# A31G324 register map
Vendor: ABOV Semiconductor Co., Ltd.; Series: A31G324; File version: 1.0
CPU: CM0PLUS r0p1, little endian, no MPU, no FPU, VTOR, 2 interrupt priority bits
Registers are 32-bit, read-write, reset 0x0 unless marked. A register's access mark holds for its fields unless they carry their own. Offsets are from the block's base; [hi:lo] are bit positions; {n}, {i} and the like mark numbered series.

## PA — General Port A
Base 0x40001000
Same registers: PB 0x40001100, PC 0x40001200
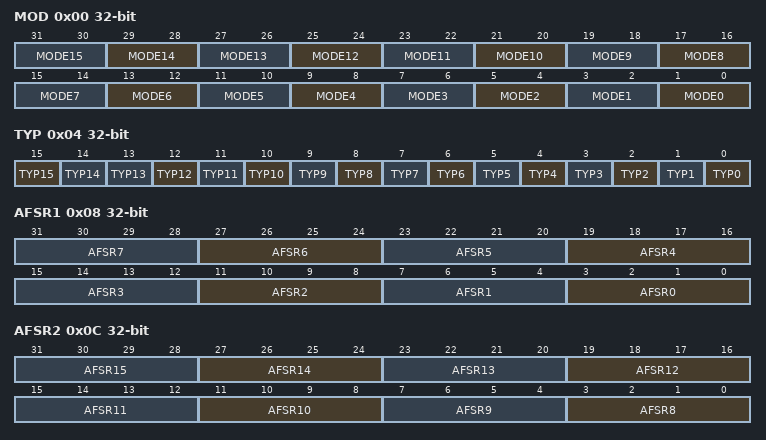
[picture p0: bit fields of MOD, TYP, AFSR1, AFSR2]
0x00 MOD — Port n Mode Register
  [2n+1:2n] MODE{n} (n=0..15) — Pin {n} Mode Selection bits
0x04 TYP — Port n Output Type Selection Register
  [15] TYP15 — Pin 15 Output Type Selection bit
  [14] TYP14 — Pin 15 Output Type Selection bit
  [n] TYP{n} (n=0..13) — Pin {n} Output Type Selection bit
0x08 AFSR1 — Port n Alternative Function Selection Register 1
  [4n+3:4n] AFSR{n} (n=0..7) — Pin {n} Alternative Function Selection bits
0x0C AFSR2 — Port n Alternative Function Selection Register 2
  [4n-29:4n-32] AFSR{n} (n=8..15) — Pin {n} Alternative Function Selection bits
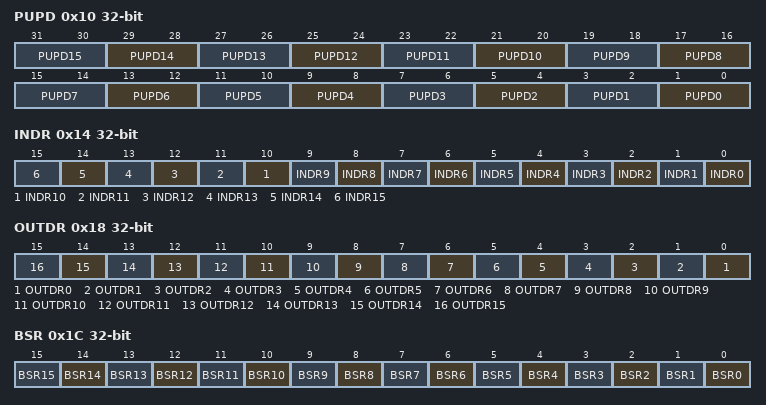
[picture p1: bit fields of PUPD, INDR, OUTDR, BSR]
0x10 PUPD — Port n Pull-up/down Resistor Selection Register
  [2n+1:2n] PUPD{n} (n=0..15) — Pin {n} Pull-up/down Resistor Selection bits
0x14 INDR ro — Port n Input Data Register
  [n] INDR{n} (n=0..15) — Pin {n} Input Data bit
0x18 OUTDR — Port n Output Data Register
  [n] OUTDR{n} (n=0..15) — Pin {n} Output Data bit
0x1C BSR wo — Port n Output Bit Set Register
  [n] BSR{n} (n=0..15) — Pin {n} Output Set bit. This bit is always read to 0
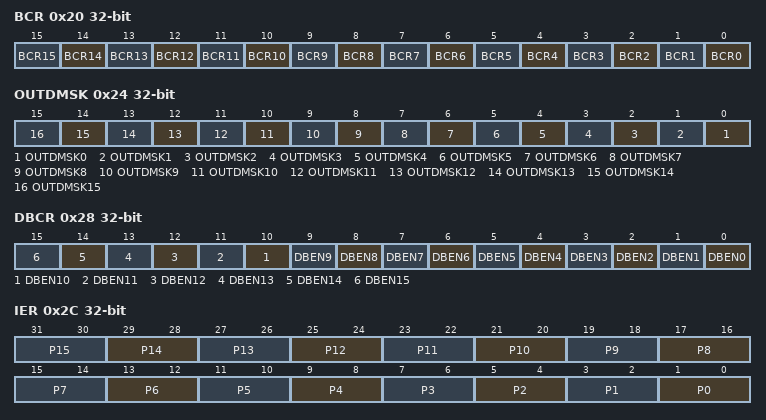
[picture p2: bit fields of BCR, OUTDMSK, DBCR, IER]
0x20 BCR wo — Port n Output Bit Clear Register
  [n] BCR{n} (n=0..15) — Pin {n} Output Clear bit. This bit is always read to 0.
0x24 OUTDMSK — Port n Output Data Mask Register
  [n] OUTDMSK{n} (n=0..15) — Pin {n} Output Data Mask bit
0x28 DBCR — Port n Debounce Control Register
  [n] DBEN{n} (n=0..15) — Pin {n} Debounce Enable bit
0x2C IER — Port n interrupt enable register
  [2n+1:2n] P{n} (n=0..15) — P{n} interrupt enable
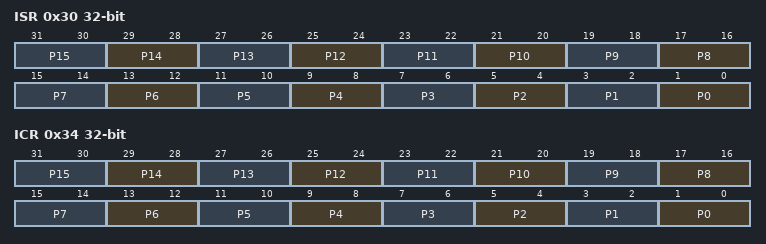
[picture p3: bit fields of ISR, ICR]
0x30 ISR — Port n interrupt status register
  [2n+1:2n] P{n} (n=0..15) — P{n} interrupt status
0x34 ICR — Port n interrupt control register
  [2n+1:2n] P{n} (n=0..15) — P{n} interrupt control

## PF
Base 0x40001500
Registers as PA; these are added or differ:
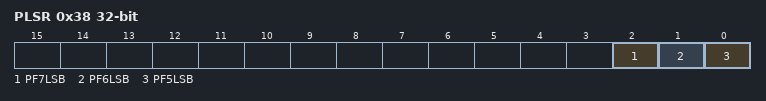
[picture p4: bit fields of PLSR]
0x38 PLSR — PORT F level select register
  [2] PF7LSB — PORTF 7 Level Select bit
  [1] PF6LSB — PORTF 6 Level Select bit
  [0] PF5LSB — PORTF 5 Level Select bit
0x40 USBCON (reset mask 0xEF7777) — USB CONTROL Register

## PCU — Port Control Mode Enable Register
Base 0x40001FF0
0x00 PORTEN wo — Port Access Enable 0x15, 0x51
  [7:0] PORTEN — Writing the sequence of 0x15 and 0x51 in this register enables writing to PCU registers, and writing other values protects all PCU registers from writing.

## FMC — FLASH MEMORY CONTROLLER
Base 0x40000100
0x04 MR reset 0x1000000 — Flash Memory Mode Select register
  [6:0] ACODE — Access Code. 5A->A5 : Flash mode entry A5->5A : Trim mode entry 81->28 : AMBA mode entry 66->99 : PROT mode entry 39->7D : test mode entry(hidden)
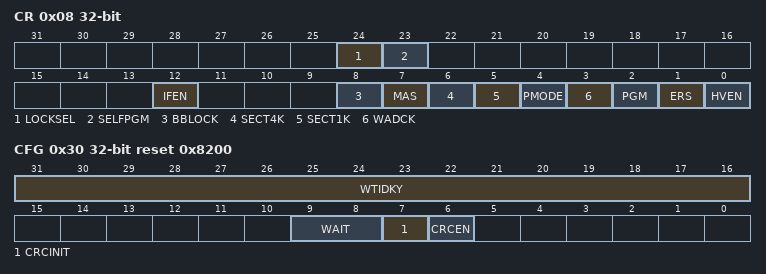
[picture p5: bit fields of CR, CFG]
0x08 CR — Flash Memory Control register
  [24] LOCKSEL — LOCK(read protection) access enable.
  [23] SELFPGM — When this bit is set("1"), PGM/ERS/HVEN will be cleared automatically after WRBUSY falling edge. It also enable CPU wait control when HVEN bit is set(1) (start of program or erase operation)It also affects to PMODE bit operation.
  [12] IFEN — Info(OTP1/2/3) block enable
  [8] BBLOCK — Boot Block(1st 4KB) protection enable/disable from Mass(bulk) erase
  [7] MAS — Mass(bulk) erase enable/disable
  [6] SECT4K — Sector 4K erase enable/disable
  [5] SECT1K — Sector 1K erase enable/disable
  [4] PMODE — PMODE enable/disable (Flash Address path is connected with FMAR) PMODE only valid when SELFPGM bit was not set(when SELFPGM = 0)
  [3] WADCK — Program/Erase address data latch clock enable/disable
  [2] PGM — Program mode enable/disable
  [1] ERS — Erase mode enable/disable
  [0] HVEN — High Voltage cycle enable/disable
0x0C AR — Flash Memory Address register
  [15:0] FADDR — Word(32-bit) base address : 64K-word address for 256KB Flash. Auto Incremental after WADCK trigger (after latching of target address).
0x10 DR — Flash Memory Data register
  [31:0] FDATA — Word size(32-bit) data
0x18 BUSY — Flash Write Busy Status Register
  [0] WRBUSY — Write Busy status bit FLBUSY bit goes high after set HVEN bit (in CTRL register). FLBUSY bit goes low when WRBUSY becomes low after program(or erase) complete.
0x20 CRC reset 0xFFFF — Flash CRC16 check value
  [15:0] CRC16 — CRC16 check value read register polynomial: (1 + x5 + x12 + x16) data width: 32 (the first serial bit is D[31])
0x30 CFG reset 0x8200 — Flash Memory Config Register
  [31:16] WTIDKY — Write Identification Key. On writes, write 0x7858 to these bits, otherwise the write is ignored.
  [9:8] WAIT — This bits only be written in AMBA mode and MSB 16-bit (bit [31:16]) must be 0x7858 00 : flash access in 1 cycle (0-wait) / 01 : flash access in 2 cycles (1-wait) / 10 : flash access in 3 cycles (2-wait) - default / 11, flash access in 4 cycles (3-wait)
  [7] CRCINIT — When this bit is set('1'), CRC register will be initialized It should be reset again before read flash to generate CRC16 calculation (Initial value of FMCRC is 0xFFFF)
  [6] CRCEN — CRC16 enable CRC value will be calculated at every flash read timing
0x34 WPROT — Write Protection Register
  [31:0] WPROT — Write protection each 8 KB segments for whole memory address (needs 16 bits for 128KB flash)
0x3C LOCK reset 0xFF — Flash LOCK register
  [7:0] RPROT — Read protection 0x0000_00FF is Default. Any other value will lock falsh(enable read protection) In user mode, 0xFF can not be written To unlock, user must erase LOCK area of Flash next to MAS(bulk) erase - 1st MAS(bult) erase and then erase LOCK area - To unlock the flash, pin reset or power on reset required
